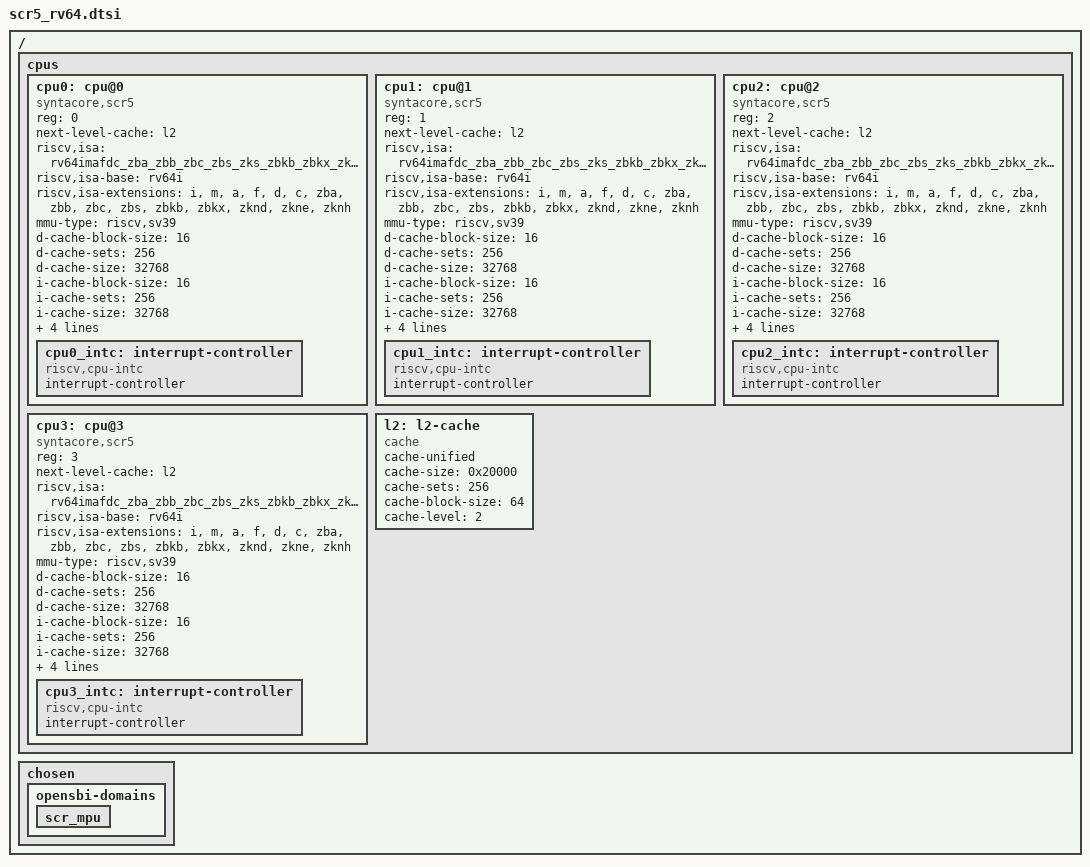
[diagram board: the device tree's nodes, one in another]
// SPDX-License-Identifier: GPL-2.0
/*
 *  Copyright (C) 2026 Syntacore
 */

/ {
	#address-cells = <2>;
	#size-cells = <2>;

	cpus {
		#address-cells = <1>;
		#size-cells = <0>;

		cpu0: cpu@0 {
			reg = <0>;
			device_type = "cpu";
			status = "okay";
			next-level-cache = <&l2>;
			compatible = "syntacore,scr5", "riscv";
			riscv,isa = "rv64imafdc_zba_zbb_zbc_zbs_zks_zbkb_zbkx_zknd_zkne_zknh";
			riscv,isa-base = "rv64i";
			riscv,isa-extensions = "i", "m", "a", "f", "d", "c", "zba", "zbb", "zbc", "zbs", "zbkb", "zbkx", "zknd", "zkne", "zknh";
			mmu-type = "riscv,sv39";
			d-cache-block-size = <16>;
			d-cache-sets = <256>;
			d-cache-size = <32768>;
			i-cache-block-size = <16>;
			i-cache-sets = <256>;
			i-cache-size = <32768>;
			riscv,cbom-block-size = <32>;
			scr,software-pagewalker;
			opensbi-domain = <&tdomain>;
			clock-frequency = <SYSCLK>;

			cpu0_intc: interrupt-controller {
				compatible = "riscv,cpu-intc";
				interrupt-controller;
				#interrupt-cells = <1>;
				#address-cells = <0>;
			};
		};

		cpu1: cpu@1 {
			reg = <1>;
			device_type = "cpu";
			status = "okay";
			next-level-cache = <&l2>;
			compatible = "syntacore,scr5", "riscv";
			riscv,isa = "rv64imafdc_zba_zbb_zbc_zbs_zks_zbkb_zbkx_zknd_zkne_zknh";
			riscv,isa-base = "rv64i";
			riscv,isa-extensions = "i", "m", "a", "f", "d", "c", "zba", "zbb", "zbc", "zbs", "zbkb", "zbkx", "zknd", "zkne", "zknh";
			mmu-type = "riscv,sv39";
			d-cache-block-size = <16>;
			d-cache-sets = <256>;
			d-cache-size = <32768>;
			i-cache-block-size = <16>;
			i-cache-sets = <256>;
			i-cache-size = <32768>;
			riscv,cbom-block-size = <32>;
			scr,software-pagewalker;
			opensbi-domain = <&tdomain>;
			clock-frequency = <SYSCLK>;

			cpu1_intc: interrupt-controller {
				compatible = "riscv,cpu-intc";
				interrupt-controller;
				#interrupt-cells = <1>;
				#address-cells = <0>;
			};
		};

		cpu2: cpu@2 {
			reg = <2>;
			device_type = "cpu";
			status = "okay";
			next-level-cache = <&l2>;
			compatible = "syntacore,scr5", "riscv";
			riscv,isa = "rv64imafdc_zba_zbb_zbc_zbs_zks_zbkb_zbkx_zknd_zkne_zknh";
			riscv,isa-base = "rv64i";
			riscv,isa-extensions = "i", "m", "a", "f", "d", "c", "zba", "zbb", "zbc", "zbs", "zbkb", "zbkx", "zknd", "zkne", "zknh";
			mmu-type = "riscv,sv39";
			d-cache-block-size = <16>;
			d-cache-sets = <256>;
			d-cache-size = <32768>;
			i-cache-block-size = <16>;
			i-cache-sets = <256>;
			i-cache-size = <32768>;
			riscv,cbom-block-size = <32>;
			scr,software-pagewalker;
			opensbi-domain = <&tdomain>;
			clock-frequency = <SYSCLK>;

			cpu2_intc: interrupt-controller {
				compatible = "riscv,cpu-intc";
				interrupt-controller;
				#interrupt-cells = <1>;
				#address-cells = <0>;
			};
		};

		cpu3: cpu@3 {
			reg = <3>;
			device_type = "cpu";
			status = "okay";
			next-level-cache = <&l2>;
			compatible = "syntacore,scr5", "riscv";
			riscv,isa = "rv64imafdc_zba_zbb_zbc_zbs_zks_zbkb_zbkx_zknd_zkne_zknh";
			riscv,isa-base = "rv64i";
			riscv,isa-extensions = "i", "m", "a", "f", "d", "c", "zba", "zbb", "zbc", "zbs", "zbkb", "zbkx", "zknd", "zkne", "zknh";
			mmu-type = "riscv,sv39";
			d-cache-block-size = <16>;
			d-cache-sets = <256>;
			d-cache-size = <32768>;
			i-cache-block-size = <16>;
			i-cache-sets = <256>;
			i-cache-size = <32768>;
			riscv,cbom-block-size = <32>;
			scr,software-pagewalker;
			opensbi-domain = <&tdomain>;
			clock-frequency = <SYSCLK>;

			cpu3_intc: interrupt-controller {
				compatible = "riscv,cpu-intc";
				interrupt-controller;
				#interrupt-cells = <1>;
				#address-cells = <0>;
			};
		};

		l2: l2-cache {
			compatible = "cache";
			cache-unified;
			cache-size = <0x20000>;
			cache-sets = <256>;
			cache-block-size = <64>;
			cache-level = <2>;
		};
	};

	chosen {
		opensbi-domains {
			scr_mpu {
			};
		};
	};
};

